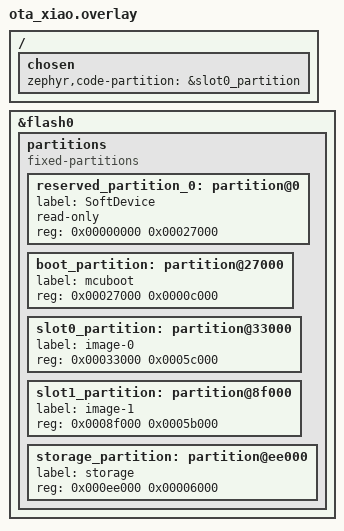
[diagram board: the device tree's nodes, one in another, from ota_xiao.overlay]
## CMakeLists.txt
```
#
# Copyright (c) 2023 Nordic Semiconductor
#
# SPDX-License-Identifier: LicenseRef-Nordic-5-Clause
#
cmake_minimum_required(VERSION 3.20.0)

# Configure VERSION from repository branch and tag
find_package(Git)

if(GIT_EXECUTABLE)
  execute_process(
    COMMAND ${GIT_EXECUTABLE} branch --show-current
    WORKING_DIRECTORY ${CMAKE_SOURCE_DIR}
    OUTPUT_VARIABLE GIT_BRANCH
    )
  execute_process(
    COMMAND ${GIT_EXECUTABLE} describe --dirty --tags --long --match [0-9]*.[0-9]*.[0-9]*
    WORKING_DIRECTORY ${CMAKE_SOURCE_DIR}
    OUTPUT_VARIABLE GIT_VERSION
    )
endif()

# Or from the environment, when git cannot read the checkout (e.g. a Windows git worktree built
# in WSL): FW_GIT_DESCRIBE as the describe command above prints it, and FW_GIT_BRANCH
if(DEFINED ENV{FW_GIT_DESCRIBE})
  set(GIT_VERSION "$ENV{FW_GIT_DESCRIBE}")
  set(GIT_BRANCH "$ENV{FW_GIT_BRANCH}")
endif()

if(GIT_BRANCH STREQUAL "")
  set(GIT_BRANCH unknown)
  message(WARNING "Unknown Git Branch")
endif()

if(GIT_VERSION STREQUAL "")
  set(GIT_VERSION 0.0.0-0)
  message(WARNING "Unknown Tag/Version")
endif()

string(STRIP ${GIT_BRANCH} GIT_BRANCH)
string(STRIP ${GIT_VERSION} GIT_VERSION)
string(REPLACE "-" ";" GIT_VERSION ${GIT_VERSION})
list(GET GIT_VERSION 0 GIT_RELEASE)
list(GET GIT_VERSION 1 GIT_TWEAK)
string(REPLACE "v" "" GIT_RELEASE ${GIT_RELEASE})
string(REPLACE "." ";" GIT_RELEASE ${GIT_RELEASE})
list(GET GIT_RELEASE 0 GIT_MAJOR)
list(GET GIT_RELEASE 1 GIT_MINOR)
list(GET GIT_RELEASE 2 GIT_PATCH)

configure_file(${CMAKE_SOURCE_DIR}/VERSION_SRC ${CMAKE_SOURCE_DIR}/VERSION @ONLY)

# Zephyr
find_package(Zephyr REQUIRED HINTS $ENV{ZEPHYR_BASE})
project(NONE)

# NORDIC SDK APP START
FILE(GLOB_RECURSE app_sources src/*.c)
target_sources(app PRIVATE ${app_sources})

# NORDIC SDK APP END

FILE(GLOB_RECURSE files vqf-c/src/*.c)
target_sources(app PRIVATE ${files})

target_include_directories(app PRIVATE src)
target_include_directories(app PRIVATE vqf-c/src)

# Force recompile for updated build timestamp
add_custom_target(touch_util_h ALL
    COMMAND ${CMAKE_COMMAND} -E touch ${CMAKE_SOURCE_DIR}/src/build_defines.h
)

target_include_directories(app PRIVATE ${CMAKE_CURRENT_SOURCE_DIR}/../shared)
include(${CMAKE_CURRENT_SOURCE_DIR}/../shared/tdma_hw.cmake)
```

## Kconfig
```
#
# Copyright (c) 2023 Nordic Semiconductor
#
# SPDX-License-Identifier: LicenseRef-Nordic-5-Clause
#

config USE_SLIMENRF_CONSOLE
    bool "Use basic console"
    default y
    help
        Use basic console for commands.

config BATTERY_CHARGER_HAS_NTC
    bool "Battery thermistor"
    help
      Flag for battery NTC thermistor availability.

choice
    prompt "Battery voltage mapping"
    default BATTERY_NO_MAPPING

config BATTERY_USE_REG_BUCK_MAPPING
    bool "Use buck regulator mapping (3.7V battery, DCDC)"
    help
      Use a constant power mapping for battery voltage.
      Preffered for systems with a buck regulator.
      Measured at a system voltage of 3.0V.

config BATTERY_USE_REG_LDO_MAPPING
    bool "Use LDO linear regulator mapping (3.7V battery, LDO)"
    help
      Use a constant current mapping for battery voltage.
      Preferred for systems with a linear regulator.

config BATTERY_NO_MAPPING
    bool "Disable battery voltage mapping"
    help
      Always map to 100% battery. Disables battery monitoring.

endchoice

config BATTERY_LOW_RUNTIME_THRESHOLD
    int "Low battery runtime threshold (ms)"
    default 10800000
    help
      Trigger low battery when estimated runtime falls below threshold.
      If estimated runtime is not available, low battery will trigger under 10% estimated state of charge.

choice
    prompt "Status LED color mapping"
    default LED_TRI_COLOR

config LED_RGB_COLOR
    bool "Use RGB color mapping"
    help
        Use RGB or RG color mapping for LED status if available.

config LED_TRI_COLOR
    bool "Use default color mapping"
    help
        Use the default color mapping for LED status.

endchoice

menu "Status LED default status color"
    depends on LED_RGB_COLOR

config LED_DEFAULT_COLOR_R
    int "Red value"
    range 0 10000
    default 4000
    depends on LED_RGB_COLOR
    help
        Red color for default status.
        Valid range is 0 to 10000.

config LED_DEFAULT_COLOR_G
    int "Green value"
    range 0 10000
    default 6000
    depends on LED_RGB_COLOR
    help
        Green color for default status.
        Valid range is 0 to 10000.

config LED_DEFAULT_COLOR_B
    int "Blue value"
    range 0 10000
    default 0
    depends on LED_RGB_COLOR
    help
        Blue color for default status.
        Valid range is 0 to 10000.

endmenu

config USER_EXTRA_ACTIONS
    bool "Multiple press actions"
    help
        Allow user to use multiple presses to calibrate, pair, or enter DFU.
        By default, pairing is available when holding down sw0 for 5 seconds.
        By default, DFU is available when holding down sw0 and plugging in a USB cable.

config IGNORE_RESET
    bool "Ignore reset"
    default y
    help
        If sw0 is available, don't perform any extra actions on reset.

config USER_SHUTDOWN
    bool "User shutdown support"
    default y
    help
        Allow user to use reset or sw0 to shutdown.

config USE_IMU_WAKE_UP
    bool "IMU wake up support"
    default y
    help
        Use IMU wake up state if IMU wake up is present.

config DELAY_SLEEP_ON_STATUS
    bool "Delay IMU wake up mode on status flags"
    default y
    depends on USE_IMU_WAKE_UP
    help
        Delay IMU wake up state if there is an active status flag or in pairing mode.

config WOM_USE_DCDC
    bool "Use DCDC in IMU wake up mode"
    depends on USE_IMU_WAKE_UP
    help
        Use DCDC instead of LDO in IMU wake up state if it is more efficient.

config CONNECTION_TIMEOUT_DELAY
    int "Connection timeout delay (ms)"
    default 300000
    depends on USER_SHUTDOWN
    help
        Connection timeout duration when receiver is not detected.

config TRACKER_OTA
    bool "Firmware updates over the radio (OTA)"
    default y if BOOTLOADER_MCUBOOT
    depends on BOOTLOADER_MCUBOOT
    select FLASH
    select FLASH_MAP
    select STREAM_FLASH
    select IMG_MANAGER
    select IMG_ERASE_PROGRESSIVELY
    help
        Set by the MCUboot build (make tracker-ota). The running image confirms itself once the
        receiver has acknowledged TRACKER_OTA_CONFIRM_ACKS frames; until then MCUboot swaps the
        previous image back on the next reboot. See docs/OTA.md.

config TRACKER_OTA_CONFIRM_ACKS
    int "Acknowledged frames before a new image confirms itself"
    depends on TRACKER_OTA
    default 200
    help
        0 never confirms (for testing the rollback).

config TRACKER_REMOTE_CONFIG
    bool "Settings over the radio"
    default y
    help
        The tracker's settings (list_config) can be read, written and reset from the PC through
        the receiver (tools/remote_config.py, receiver console "cfg"). Works with or without the
        MCUboot build. See docs/OTA.md.

config SENSOR_UPDATE_TIME_MS
    int "Sensor loop period while moving (ms)"
    range 6 33
    default 10
    help
        Default of the sensor_update_time_ms setting (write_config sensor_update_time_ms <6-33>,
        takes effect without a restart). The sensor loop wakes up this often while the tracker
        moves, and sends the orientation when it changed: 10 ms is 100 Hz. Fusion still
        processes every IMU sample from the FIFO; only how often orientations are sent changes.
        Upstream uses 6 ms (about 166 Hz), which with several trackers on one channel fills it
        and makes them collide. Still trackers switch to 33 ms and 100 ms as before.

choice
    prompt "Sensor rotation"
    default SENSOR_ROTATION_90

config SENSOR_ROTATION_0
    bool "0 degrees"

config SENSOR_ROTATION_90
    bool "90 degrees"

config SENSOR_ROTATION_180
    bool "180 degrees"

config SENSOR_ROTATION_270
    bool "270 degrees"

config SENSOR_ROTATION_0_FLIPPED
    bool "0 degrees flipped"

config SENSOR_ROTATION_90_FLIPPED
    bool "90 degrees flipped"

config SENSOR_ROTATION_180_FLIPPED
    bool "180 degrees flipped"

config SENSOR_ROTATION_270_FLIPPED
    bool "270 degrees flipped"

endchoice

menu "Sensor power saving"

config SENSOR_LP_TIMEOUT
    int "Sensor low power delay (ms)"
    default 500
    help
        Low power timeout during no motion.

config SENSOR_USE_LOW_POWER_2
    bool "Use additional low power modes"
    help
        Use a higher latency sensor mode during no motion.

config USE_IMU_TIMEOUT
    bool "Use IMU wake up state"
    default y
    depends on USE_IMU_WAKE_UP
    help
        Use IMU wake up state during no motion.

config IMU_TIMEOUT_RAMP_MIN
    int "Sensor timeout minimum delay (ms)"
    default 5000
    depends on USE_IMU_TIMEOUT || SENSOR_USE_LOW_POWER_2
    help
        Minimum timeout during no motion. Initial period on wake up.

config IMU_TIMEOUT_RAMP_MAX
    int "Sensor timeout maximum delay (ms)"
    default 15000
    depends on USE_IMU_TIMEOUT || SENSOR_USE_LOW_POWER_2
    help
        Maximum timeout during no motion.

config USE_ACTIVE_TIMEOUT
    bool "Use activity timeout"
    default y
    depends on USE_IMU_WAKE_UP || USER_SHUTDOWN
    help
        Delay IMU wake up state or user shutdown during activity.

choice
    prompt "Activity timeout mode"
    default SLEEP_ON_ACTIVE_TIMEOUT
    depends on USE_ACTIVE_TIMEOUT

config SLEEP_ON_ACTIVE_TIMEOUT
    bool "IMU wake up"
    depends on USE_IMU_WAKE_UP
    help
        Use IMU wake up state when activity timeout elapses.

config SHUTDOWN_ON_ACTIVE_TIMEOUT
    bool "User shutdown"
    depends on USER_SHUTDOWN
    help
        Use user shutdown when activity timeout elapses.

endchoice

config ACTIVE_TIMEOUT_THRESHOLD
    int "Activity timeout threshold (ms)"
    default 15000
    depends on USE_ACTIVE_TIMEOUT
    help
        Trigger activity timeout after a certain threshold of activity.

config ACTIVE_TIMEOUT_DELAY
    int "Activity timeout delay (ms)"
    default 900000
    depends on USE_ACTIVE_TIMEOUT
    help
        Activity timeout duration when triggered.

endmenu

config SENSOR_ACCEL_ODR
    int "Accelerometer output data rate (Hz)"
    default 100
    help
        Requested accelerometer output data rate. Actual rate will be raised to the nearest supported rate.
        A higher rate will increase the time to read and process sensor data.

config SENSOR_GYRO_ODR
    int "Gyrometer output data rate (Hz)"
    default 200
    help
        Requested gyrometer output data rate. Actual rate will be raised to the nearest supported rate.
        A higher rate will increase the time to read and process sensor data.
        A lower rate is recommended for IMUs with poor gyrometer rate noise density. (e.g. BMI270, LSM6DS3TR-C)

config SENSOR_ACCEL_FS
    int "Accelerometer full scale (g)"
    default 4
    help
        Requested accelerometer full scale. Actual scale will be raised to the nearest supported scale.
        A lower scale may improve noise performance, but is more likely to saturate.

config SENSOR_GYRO_FS
    int "Gyrometer full scale (dps)"
    default 1000
    help
        Requested gyrometer full scale. Actual scale will be raised to the nearest supported scale.
        A lower scale may improve noise performance, but is more likely to saturate.

config SENSOR_USE_MAG
    bool "Magnetometer support"
    default y
    help
        Use magnetometer if it is present.

config USE_SENSOR_CLOCK
    bool "Use external IMU clock"
    default y
    help
        Use external IMU clock if it is present.

choice
    prompt "Sensor fusion"
    default SENSOR_USE_VQF
    help
        Select the sensor fusion method.

config SENSOR_USE_VQF
    bool "Use VQF"
    help
        Use VQF for sensor fusion.
        Based on Kalman filter.

endchoice

config SENSOR_USE_6_SIDE_CALIBRATION
    bool "Use 6-side calibration"
    default y
    depends on USE_SLIMENRF_CONSOLE
    help
        Use 6-side calibration for accelerometer.
        Calibration can be completed through the basic console.

config RADIO_TX_POWER
    int "Radio output power (dBm)"
    default 8
    help
        Radio output power level.
        A lower value may reduce power consumption.

config CONNECTION_OVER_HID
    bool "Use HID for data output"
    help
        Use HID if available.
        Otherwise, use ESB only.

config TRACKER_BLE
    bool "BLE connection mode"
    default y if SOC_NRF52840
    select BT
    select BT_PERIPHERAL
    select BT_DEVICE_NAME_DYNAMIC
    select ESB_DYNAMIC_INTERRUPTS
    select MPSL_DYNAMIC_INTERRUPTS
    help
        Builds the BLE stack in beside ESB. The connection_over_ble setting (console: ble on|off)
        picks one at boot: the radio runs either ESB to the receiver or BLE to a PC
        (tools/ble_bridge.py), never both. Changing it reboots the tracker.

        MPSL keeps its own (default) clock control in both modes: it runs the 32 MHz crystal
        that USB and the radio share. In ESB mode MPSL stays initialized but idle, and ESB takes
        the radio interrupt over (dynamic interrupts). MPSL_USE_EXTERNAL_CLOCK_CONTROL
        (experimental on nRF52) left USB stalled and BLE connections failing: not used.

config CONNECTION_OVER_BLE
    bool "Start in BLE mode"
    depends on TRACKER_BLE
    help
        Default of the connection_over_ble setting.

if TRACKER_BLE

config BT_DEVICE_NAME
    default "SlimeNRF"

# ble.c names the tracker SlimeNRF-<last 4 hex digits of its address>; not renamable over the air
config BT_DEVICE_NAME_GATT_WRITABLE
    default n

# 7.5-15 ms: one notification per connection event keeps up with the ~120 Hz moving rate
config BT_PERIPHERAL_PREF_MIN_INT
    default 6

config BT_PERIPHERAL_PREF_MAX_INT
    default 12

config BT_PERIPHERAL_PREF_TIMEOUT
    default 400

choice BT_CTLR_TX_PWR
    default BT_CTLR_TX_PWR_PLUS_8
endchoice

endif

# BLE needs a calibrated RC clock (500 ppm). Without BLE it stays off for a faster boot, as before.
config CLOCK_CONTROL_NRF_K32SRC_RC_CALIBRATION
    default n if !TRACKER_BLE

source "Kconfig.zephyr"
```

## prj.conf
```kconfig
#CONFIG_NCS_SAMPLES_DEFAULTS
CONFIG_ASSERT=y
CONFIG_ASSERT_NO_COND_INFO=y
CONFIG_ASSERT_NO_MSG_INFO=y
CONFIG_RESET_ON_FATAL_ERROR=y

CONFIG_NCS_APPLICATION_BOOT_BANNER_STRING="SlimeVR-Tracker-nRF"
#CONFIG_NCS_BOOT_BANNER=n
CONFIG_BOOT_BANNER=n

# Always active, as SlimeVR's "Sleep (WOM) off" builds: no wake-on-motion power-off when still.
# The activity timeout goes too: without WOM it would fall back to a full shutdown after 15 min
# still. The shutdown after losing the receiver (connection_timeout_delay) stays.
CONFIG_USE_IMU_WAKE_UP=n
CONFIG_USE_ACTIVE_TIMEOUT=n

CONFIG_ESB=y
#need to enable for nRF54L
#CONFIG_NRFX_DPPI10=y

CONFIG_ADC=y
CONFIG_ADC_NRFX_SAADC=y
CONFIG_FPU=y
CONFIG_I2C=y
CONFIG_SPI=y
CONFIG_PINCTRL=y
CONFIG_SENSOR=y

CONFIG_CMSIS_DSP=y
CONFIG_CMSIS_DSP_BASICMATH=y
CONFIG_CMSIS_DSP_CONTROLLER=y
CONFIG_CMSIS_DSP_FASTMATH=y
CONFIG_CMSIS_DSP_SUPPORT=y

CONFIG_NVS=y
CONFIG_NVS_LOOKUP_CACHE=y
CONFIG_NVS_INIT_BAD_MEMORY_REGION=y

CONFIG_POWEROFF=y
CONFIG_REBOOT=y

CONFIG_FLASH=y
CONFIG_FLASH_PAGE_LAYOUT=y
CONFIG_FLASH_MAP=y

CONFIG_SETTINGS=y
CONFIG_SETTINGS_RUNTIME=y
CONFIG_SETTINGS_NONE=y

CONFIG_MPU_ALLOW_FLASH_WRITE=y

CONFIG_RETAINED_MEM=y

CONFIG_USE_SEGGER_RTT=y
CONFIG_LOG=y
#CONFIG_PRINTK=y
CONFIG_LOG_MODE_DEFERRED=y
CONFIG_LOG_SPEED=y
CONFIG_LOG_BACKEND_RTT=y
CONFIG_CBPRINTF_FP_SUPPORT=y
CONFIG_ADC_LOG_LEVEL_OFF=y
CONFIG_LOG_FUNC_NAME_PREFIX_ERR=y
CONFIG_LOG_BUFFER_SIZE=1536
CONFIG_LOG_BACKEND_UART_AUTOSTART=n
CONFIG_LOG_PROCESS_THREAD_SLEEP_MS=50
CONFIG_LOG_PROCESS_THREAD_STACK_SIZE=1024

CONFIG_PWM=y
CONFIG_GPIO=y

CONFIG_CRC=y

CONFIG_NEWLIB_LIBC=y
#deprecated?
#CONFIG_NRFX_TIMER1=y

#speed up boot? (use internal rc oscillator)
CONFIG_CLOCK_CONTROL_NRF_K32SRC_RC=y
# calibration: off unless the BLE mode is built in (Kconfig, TRACKER_BLE)
#speed up boot? (synthesize lf clock)
#CONFIG_CLOCK_CONTROL_NRF_K32SRC_SYNTH=y

# dont need it
CONFIG_CRYPTO=n

# set timeout for 25ms, sufficient for ~1000 bytes
CONFIG_I2C_NRFX_TRANSFER_TIMEOUT=25

CONFIG_USB_DEVICE_HID=y
CONFIG_USB_DEVICE_VID=0x1209
CONFIG_USB_DEVICE_PID=0x7692
CONFIG_USB_HID_BOOT_PROTOCOL=y
CONFIG_USB_DEVICE_INITIALIZE_AT_BOOT=n
CONFIG_USB_CDC_ACM=y
CONFIG_UART_INTERRUPT_DRIVEN=y
CONFIG_USB_WORKQUEUE_STACK_SIZE=512

CONFIG_SERIAL=y
CONFIG_CONSOLE=y
CONFIG_RTT_CONSOLE=y
CONFIG_UART_CONSOLE=y
CONFIG_UART_LINE_CTRL=y
# fit "write all <base64:173>"
CONFIG_CONSOLE_INPUT_MAX_LINE_LEN=256

CONFIG_LOG=y
CONFIG_USB_DRIVER_LOG_LEVEL_ERR=y
CONFIG_USB_DEVICE_LOG_LEVEL_ERR=y
CONFIG_USB_CDC_ACM_LOG_LEVEL_OFF=y

CONFIG_LOG_BACKEND_UART=y

CONFIG_CONSOLE_SUBSYS=y
CONFIG_CONSOLE_GETLINE=y

CONFIG_NVS_LOG_LEVEL_WRN=y
CONFIG_USB_HID_LOG_LEVEL_WRN=y

CONFIG_USB_DEVICE_SOF=y
CONFIG_USB_HID_REPORTS=256

#CONFIG_USB_HID_POLL_INTERVAL_MS=1
CONFIG_USB_HID_POLL_INTERVAL_MS=0
CONFIG_HID_INTERRUPT_EP_MPS=64
#CONFIG_ENABLE_HID_INT_OUT_EP=y

# the BLE host (TRACKER_BLE) runs on the system workqueue; upstream had 256
CONFIG_SYSTEM_WORKQUEUE_STACK_SIZE=1024
CONFIG_MAIN_STACK_SIZE=512
#crashing on nrf54l at 512

CONFIG_THREAD_NAME=y

# Hardware watchdog (src/system/watchdog.c): a tracker whose threads stop running resets itself
CONFIG_WATCHDOG=y

CONFIG_HEAP_MEM_POOL_SIZE=2048
CONFIG_ISR_STACK_SIZE=1024

CONFIG_PM_DEVICE=y

CONFIG_BASE64=y

#CONFIG_THREAD_ANALYZER=y
#CONFIG_THREAD_ANALYZER_AUTO=y
#CONFIG_THREAD_ANALYZER_AUTO_INTERVAL=5

#about 20KB saved
#CONFIG_LTO=y
#CONFIG_ISR_TABLES_LOCAL_DECLARATION=y
```

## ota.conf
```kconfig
# Tracker app in the OTA build (make tracker-ota passes it as Tracker_EXTRA_CONF_FILE): the
# partition manager places it behind MCUboot (pm_static/mcuboot_*.yml), not at the UF2 offset the
# board defconfig sets.
CONFIG_FLASH_LOAD_OFFSET=0x0
```

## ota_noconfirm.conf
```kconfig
# Rollback test (make tracker-ota-slot1 OTA_NOCONFIRM=1): this image never confirms itself, so
# MCUboot swaps the previous one back on the next reboot.
CONFIG_TRACKER_OTA_CONFIRM_ACKS=0
```

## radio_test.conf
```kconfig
CONFIG_RADIO_TDMA=y
CONFIG_RADIO_TEST=y
CONFIG_RADIO_TEST_HZ=100
CONFIG_STACK_USAGE=y
```

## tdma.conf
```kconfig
# Experimental; requires the matching receiver and TDMA firmware on every tracker.
CONFIG_RADIO_TDMA=y
CONFIG_STACK_USAGE=y
```

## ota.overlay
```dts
/* Tracker app in the OTA build (make tracker-ota passes it as Tracker_EXTRA_DTC_OVERLAY_FILE): the
 * partition labels MCUboot's image tools need, the same layout as pm_static/mcuboot_nrf52840_uf2.yml
 * (which the build uses for the actual placement) and sysbuild/mcuboot.overlay. */
&flash0 {
	partitions {
		compatible = "fixed-partitions";
		#address-cells = <1>;
		#size-cells = <1>;

		boot_partition: partition@1000 {
			label = "mcuboot";
			reg = <0x00001000 0x0000c000>;
		};
		slot0_partition: partition@d000 {
			label = "image-0";
			reg = <0x0000d000 0x0006f000>;
		};
		slot1_partition: partition@7c000 {
			label = "image-1";
			reg = <0x0007c000 0x0006e000>;
		};
		storage_partition: partition@ee000 {
			label = "storage";
			reg = <0x000ee000 0x00006000>;
		};
	};
};
```

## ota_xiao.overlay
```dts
/* Tracker app in the XIAO OTA build (make tracker-ota-xiao passes it as Tracker_EXTRA_DTC_OVERLAY_FILE):
 * the partition labels MCUboot's image tools need, the same layout as pm_static/mcuboot_xiao_ble.yml
 * (which the build uses for the actual placement) and sysbuild/mcuboot_xiao.overlay. The board's
 * own table names its UF2 bootloader boot_partition, so the table is replaced, not extended. */
/ {
	chosen {
		zephyr,code-partition = &slot0_partition;
	};
};

&flash0 {
	/delete-node/ partitions;

	partitions {
		compatible = "fixed-partitions";
		#address-cells = <1>;
		#size-cells = <1>;

		reserved_partition_0: partition@0 {
			label = "SoftDevice";
			read-only;
			reg = <0x00000000 0x00027000>;
		};
		boot_partition: partition@27000 {
			label = "mcuboot";
			reg = <0x00027000 0x0000c000>;
		};
		slot0_partition: partition@33000 {
			label = "image-0";
			reg = <0x00033000 0x0005c000>;
		};
		slot1_partition: partition@8f000 {
			label = "image-1";
			reg = <0x0008f000 0x0005b000>;
		};
		storage_partition: partition@ee000 {
			label = "storage";
			reg = <0x000ee000 0x00006000>;
		};
	};
};
```

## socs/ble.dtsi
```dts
/* BLE mode (CONFIG_TRACKER_BLE, included by the nrf52840*.overlay files): random numbers from the
 * RNG peripheral. The SoC default is CryptoCell, whose driver needs nrf_security. */
/ {
	chosen {
		zephyr,entropy = &rng;
	};
};
```

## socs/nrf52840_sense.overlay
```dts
/ {
	sram0@2003f000 {
		compatible = "zephyr,memory-region", "mmio-sram";
		reg = <0x2003f000 DT_SIZE_K(4)>;
		zephyr,memory-region = "RETAINED_MEM";
		status = "okay";

		retainedmem0: retainedmem {
			compatible = "zephyr,retained-ram";
			status = "okay";
		};
	};

	sram0@20007f7c {
		compatible = "zephyr,memory-region", "mmio-sram";
		reg = <0x20007f7c 4>;
		zephyr,memory-region = "DFU_DBL_RESET_MEM";
		status = "okay";

		retainedmem {
			compatible = "zephyr,retained-ram";
			status = "okay";
		};
	};

	aliases {
		retainedmemdevice = &retainedmem0;
	};
};

&sram0 {
	/* Shrink SRAM size to avoid overlap with retained memory region */
	reg = <0x20000000 DT_SIZE_K(252)>;
};

#include "ble.dtsi" /* BLE mode (CONFIG_TRACKER_BLE) */
```

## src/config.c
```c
#include "globals.h"
#include "system/system.h"

#include "config.h"

#if DT_NODE_HAS_STATUS_OKAY(DT_ALIAS(retainedmemdevice))
#define MEMORY_REGION DT_PARENT(DT_ALIAS(retainedmemdevice))
#else
#error "retained_mem region not defined"
#endif

#define RETAINED_SETTINGS_OFFSET offsetof(struct retained_data, settings)

struct config_settings_data *config_settings = (struct config_settings_data *)(DT_REG_ADDR(MEMORY_REGION) + RETAINED_SETTINGS_OFFSET);

const uint16_t config_settings_count[] = {
	CONFIG_0_SETTINGS_END,
	CONFIG_1_SETTINGS_END,
	CONFIG_2_SETTINGS_END,
	CONFIG_3_SETTINGS_END
};

const char *config_settings_names[] = {
	"user_extra_actions", // 0
	"ignore_reset",
	"user_shutdown",
	"use_imu_wake_up",
	"delay_sleep_on_status",
	"connection_over_hid",
	"sensor_use_low_power_2", // 1
	"use_imu_timeout",
	"use_active_timeout",
	"sensor_use_mag",
	"use_sensor_clock",
	"sensor_use_6_side_calibration",
	"led_default_color_r", // 2
	"led_default_color_g",
	"led_default_color_b",
	"active_timeout_mode",
	"sensor_accel_odr",
	"sensor_gyro_odr",
	"sensor_accel_fs",
	"sensor_gyro_fs",
	"sensor_fusion",
	"radio_tx_power",
	"connection_timeout_delay", // 3
	"sensor_lp_timeout",
	"imu_timeout_ramp_min",
	"imu_timeout_ramp_max",
	"active_timeout_threshold",
	"active_timeout_delay",
	"battery_low_runtime_threshold",
	"sensor_update_time_ms",
	"connection_over_ble",
	"sensor_send_unchanged"
};

const bool config_0_settings_defaults[16] = {
	IS_ENABLED(CONFIG_USER_EXTRA_ACTIONS),
	IS_ENABLED(CONFIG_IGNORE_RESET),
	IS_ENABLED(CONFIG_USER_SHUTDOWN),
	IS_ENABLED(CONFIG_USE_IMU_WAKE_UP),
	IS_ENABLED(CONFIG_DELAY_SLEEP_ON_STATUS),
	IS_ENABLED(CONFIG_CONNECTION_OVER_HID),
};

const bool config_1_settings_defaults[16] = {
	IS_ENABLED(CONFIG_SENSOR_USE_LOW_POWER_2),
	IS_ENABLED(CONFIG_USE_IMU_TIMEOUT),
	IS_ENABLED(CONFIG_USE_ACTIVE_TIMEOUT),
	IS_ENABLED(CONFIG_SENSOR_USE_MAG),
	IS_ENABLED(CONFIG_USE_SENSOR_CLOCK),
	IS_ENABLED(CONFIG_SENSOR_USE_6_SIDE_CALIBRATION),
};

const int16_t config_2_settings_defaults[16] = {
#ifdef CONFIG_LED_DEFAULT_COLOR_R
	CONFIG_LED_DEFAULT_COLOR_R, // 0-10000
#else
	4000,
#endif
#ifdef CONFIG_LED_DEFAULT_COLOR_G
	CONFIG_LED_DEFAULT_COLOR_G, // 0-10000
#else
	6000,
#endif
#ifdef CONFIG_LED_DEFAULT_COLOR_B
	CONFIG_LED_DEFAULT_COLOR_B, // 0-10000
#else
	0,
#endif
#if CONFIG_SHUTDOWN_ON_ACTIVE_TIMEOUT
	1,
#else // CONFIG_SLEEP_ON_ACTIVE_TIMEOUT
	0,
#endif
	CONFIG_SENSOR_ACCEL_ODR, // 0-3200 (e.g.)
	CONFIG_SENSOR_GYRO_ODR, // 0-3200 (e.g.)
	CONFIG_SENSOR_ACCEL_FS, // 0-32000 (e.g.)
	CONFIG_SENSOR_GYRO_FS, // 0-32000 (e.g.)
#if CONFIG_SENSOR_USE_VQF
	3,
#elif CONFIG_SENSOR_USE_NXPSENSORFUSION
	2,
#elif CONFIG_SENSOR_USE_XIOFUSION
	1,
#else
	0,
#endif
	CONFIG_RADIO_TX_POWER, // -128-127
};

const int32_t config_3_settings_defaults[16] = {
#ifdef CONFIG_CONNECTION_TIMEOUT_DELAY
	CONFIG_CONNECTION_TIMEOUT_DELAY,
#else
	300000,
#endif
	CONFIG_SENSOR_LP_TIMEOUT,
#ifdef CONFIG_IMU_TIMEOUT_RAMP_MIN
	CONFIG_IMU_TIMEOUT_RAMP_MIN,
#else
	5000,
#endif
#ifdef CONFIG_IMU_TIMEOUT_RAMP_MAX
	CONFIG_IMU_TIMEOUT_RAMP_MAX,
#else
	15000,
#endif
#ifdef CONFIG_ACTIVE_TIMEOUT_THRESHOLD
	CONFIG_ACTIVE_TIMEOUT_THRESHOLD,
#else
	15000,
#endif
#ifdef CONFIG_ACTIVE_TIMEOUT_DELAY
	CONFIG_ACTIVE_TIMEOUT_DELAY,
#else
	900000,
#endif
	CONFIG_BATTERY_LOW_RUNTIME_THRESHOLD,
	CONFIG_SENSOR_UPDATE_TIME_MS, // 6-33, see sensor_low_noise_update_time_ms
	IS_ENABLED(CONFIG_CONNECTION_OVER_BLE), // 0-1, see ble.c
	0, // 0-1, see sensor.c
};

LOG_MODULE_REGISTER(config, LOG_LEVEL_INF);

void config_settings_init(void)
{
	for (int i = 0; i < 16; i++)
	{
		uint16_t write_mask = 1 << i;
		if (!(config_settings->config_0_ovrd & write_mask))
		{
			if (config_0_settings_defaults[i])
				config_settings->config_0_settings |= write_mask;
			else
				config_settings->config_0_settings &= ~write_mask;
		}
		if (!(config_settings->config_1_ovrd & write_mask))
		{
			if (config_1_settings_defaults[i])
				config_settings->config_1_settings |= write_mask;
			else
				config_settings->config_1_settings &= ~write_mask;
		}
		if (!(config_settings->config_2_ovrd & write_mask))
			config_settings->config_2_settings[i] = config_2_settings_defaults[i];
		if (!(config_settings->config_3_ovrd & write_mask))
			config_settings->config_3_settings[i] = config_3_settings_defaults[i];
	}
}

void config_0_settings_write(uint16_t id, bool value)
{
	uint16_t write_mask = 1 << id;

	config_settings->config_0_ovrd |= write_mask;

	if (value)
		config_settings->config_0_settings |= write_mask;
	else
		config_settings->config_0_settings &= ~write_mask;

	sys_write(SETTINGS_ID, NULL, retained->settings, sizeof(retained->settings));
}

void config_1_settings_write(uint16_t id, bool value)
{
	uint16_t write_mask = 1 << id;

	config_settings->config_1_ovrd |= write_mask;

	if (value)
		config_settings->config_1_settings |= write_mask;
	else
		config_settings->config_1_settings &= ~write_mask;

	sys_write(SETTINGS_ID, NULL, retained->settings, sizeof(retained->settings));
}

void config_2_settings_write(uint16_t id, int16_t value)
{
	uint16_t write_mask = 1 << id;

	config_settings->config_2_ovrd |= write_mask;

	config_settings->config_2_settings[id] = value;

	sys_write(SETTINGS_ID, NULL, retained->settings, sizeof(retained->settings));
}

void config_3_settings_write(uint16_t id, int32_t value)
{
	uint16_t write_mask = 1 << id;

	config_settings->config_3_ovrd |= write_mask;

	config_settings->config_3_settings[id] = value;

	sys_write(SETTINGS_ID, NULL, retained->settings, sizeof(retained->settings));
}

void config_settings_reset(uint16_t config, uint16_t id)
{
	uint16_t write_mask = 1 << id;

	switch (config)
	{
	case 0:
		config_settings->config_0_ovrd &= ~write_mask;
		break;
	case 1:
		config_settings->config_1_ovrd &= ~write_mask;
		break;
	case 2:
		config_settings->config_2_ovrd &= ~write_mask;
		break;
	case 3:
		config_settings->config_3_ovrd &= ~write_mask;
		break;
	default:
	}

	config_settings_init(); // reset non-overridden value

	sys_write(SETTINGS_ID, NULL, retained->settings, sizeof(retained->settings));
}

void config_settings_reset_all(void)
{
	static bool reset_confirm = false;
	if (!reset_confirm)
	{
		printk("Resetting device settings will clear all user-defined settings to the firmware defaults. Please resend the command to confirm.\n");
		reset_confirm = true;
		return;
	}
	printk("Resetting device settings\n");

	config_settings->config_0_ovrd = 0;
	config_settings->config_1_ovrd = 0;
	config_settings->config_2_ovrd = 0;
	config_settings->config_3_ovrd = 0;

	config_settings_init(); // reset non-overridden value

	sys_write(SETTINGS_ID, NULL, retained->settings, sizeof(retained->settings));
	reset_confirm = false;
	LOG_INF("Device settings reset");
}
```

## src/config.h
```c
#ifndef SLIMENRF_CONFIG
#define SLIMENRF_CONFIG

#include "retained.h"

#define CONFIG_SETTINGS_COUNT 4

// map of settings area
struct config_settings_data {
	uint16_t config_0_ovrd; // Override enable flags
	uint16_t config_0_settings;
	uint16_t config_1_ovrd;
	uint16_t config_1_settings;
	uint16_t config_2_ovrd;
	int16_t config_2_settings[16];
	uint16_t config_3_ovrd;
	int32_t config_3_settings[16];
};

// because settings read is a macro, need to expose settings struct
extern struct config_settings_data *config_settings;

// device settings
enum config_0_settings_id {
	CONFIG_0_USER_EXTRA_ACTIONS,
	CONFIG_0_IGNORE_RESET,
	CONFIG_0_USER_SHUTDOWN,
	CONFIG_0_USE_IMU_WAKE_UP,
	CONFIG_0_DELAY_SLEEP_ON_STATUS,
	CONFIG_0_CONNECTION_OVER_HID,
	CONFIG_0_SETTINGS_END
};

// sensor settings
enum config_1_settings_id {
	CONFIG_1_SENSOR_USE_LOW_POWER_2,
	CONFIG_1_USE_IMU_TIMEOUT,
	CONFIG_1_USE_ACTIVE_TIMEOUT,
	CONFIG_1_SENSOR_USE_MAG,
	CONFIG_1_USE_SENSOR_CLOCK,
	CONFIG_1_SENSOR_USE_6_SIDE_CALIBRATION,
	CONFIG_1_SETTINGS_END
};

enum config_2_settings_id {
	CONFIG_2_LED_DEFAULT_COLOR_R,
	CONFIG_2_LED_DEFAULT_COLOR_G,
	CONFIG_2_LED_DEFAULT_COLOR_B,
	CONFIG_2_ACTIVE_TIMEOUT_MODE, // 0: Sleep, 1: Shutdown
	CONFIG_2_SENSOR_ACCEL_ODR,
	CONFIG_2_SENSOR_GYRO_ODR,
	CONFIG_2_SENSOR_ACCEL_FS,
	CONFIG_2_SENSOR_GYRO_FS,
	CONFIG_2_SENSOR_FUSION, // 1: XIO, 3: VQF
	CONFIG_2_RADIO_TX_POWER,
	CONFIG_2_SETTINGS_END
};

enum config_3_settings_id {
	CONFIG_3_CONNECTION_TIMEOUT_DELAY,
	CONFIG_3_SENSOR_LP_TIMEOUT,
	CONFIG_3_IMU_TIMEOUT_RAMP_MIN,
	CONFIG_3_IMU_TIMEOUT_RAMP_MAX,
	CONFIG_3_ACTIVE_TIMEOUT_THRESHOLD,
	CONFIG_3_ACTIVE_TIMEOUT_DELAY,
	CONFIG_3_BATTERY_LOW_RUNTIME_THRESHOLD,
	CONFIG_3_SENSOR_UPDATE_TIME_MS, // appended so the ids of the other settings stay the same
	CONFIG_3_CONNECTION_OVER_BLE, // 0: ESB, 1: BLE; read at boot (ble on|off)
	CONFIG_3_SENSOR_SEND_UNCHANGED, // 0-1: send every update, also while the orientation stays the same (load tests)
	CONFIG_3_SETTINGS_END
};

extern const uint16_t config_settings_count[];

extern const char *config_settings_names[];

#define CONFIG_0_SETTINGS_READ(id) (config_settings->config_0_settings & (1 << id))
#define CONFIG_1_SETTINGS_READ(id) (config_settings->config_1_settings & (1 << id))
#define CONFIG_2_SETTINGS_READ(id) (config_settings->config_2_settings[id])
#define CONFIG_3_SETTINGS_READ(id) (config_settings->config_3_settings[id])

void config_settings_init(void);

void config_0_settings_write(uint16_t id, bool value);
void config_1_settings_write(uint16_t id, bool value);
void config_2_settings_write(uint16_t id, int16_t value);
void config_3_settings_write(uint16_t id, int32_t value);

void config_settings_reset(uint16_t config, uint16_t id);
void config_settings_reset_all(void);

#endif
```

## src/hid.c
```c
/*
	SlimeVR Code is placed under the MIT license
	Copyright (c) 2025 SlimeVR Contributors

	Permission is hereby granted, free of charge, to any person obtaining a copy
	of this software and associated documentation files (the "Software"), to deal
	in the Software without restriction, including without limitation the rights
	to use, copy, modify, merge, publish, distribute, sublicense, and/or sell
	copies of the Software, and to permit persons to whom the Software is
	furnished to do so, subject to the following conditions:

	The above copyright notice and this permission notice shall be included in
	all copies or substantial portions of the Software.

	THE SOFTWARE IS PROVIDED "AS IS", WITHOUT WARRANTY OF ANY KIND, EXPRESS OR
	IMPLIED, INCLUDING BUT NOT LIMITED TO THE WARRANTIES OF MERCHANTABILITY,
	FITNESS FOR A PARTICULAR PURPOSE AND NONINFRINGEMENT. IN NO EVENT SHALL THE
	AUTHORS OR COPYRIGHT HOLDERS BE LIABLE FOR ANY CLAIM, DAMAGES OR OTHER
	LIABILITY, WHETHER IN AN ACTION OF CONTRACT, TORT OR OTHERWISE, ARISING FROM,
	OUT OF OR IN CONNECTION WITH THE SOFTWARE OR THE USE OR OTHER DEALINGS IN
	THE SOFTWARE.
*/
#include "globals.h"

#if CONFIG_USB_DEVICE_STACK
#define USB DT_NODELABEL(usbd)
#define USB_EXISTS (DT_NODE_HAS_STATUS(USB, okay) && CONFIG_UART_CONSOLE)
#endif

#if USB_EXISTS
#include <zephyr/kernel.h>
#include <zephyr/usb/usb_device.h>
#include <zephyr/usb/class/usb_hid.h>

static struct tracker_report {
	uint8_t data[16];
} __packed report = {
	.data = {0}
};;

#define REPORT_SIZE sizeof(report)
#define REPORT_COUNT (3 * 4)
#define REPORT_THRESHOLD (REPORT_COUNT - 4) // buffer loop point

uint8_t reports[REPORT_COUNT * REPORT_SIZE]; // 3 report buffer (and 4 "packets" each)
uint8_t report_count = 0;
uint8_t report_sent = 0;

static const struct device *hdev;
static ATOMIC_DEFINE(hid_ep_in_busy, 1);

#define HID_EP_BUSY_FLAG 0

LOG_MODULE_REGISTER(hid_event, LOG_LEVEL_INF);

static void hid_thread(void);
static struct k_thread hid_thread_id;
static K_THREAD_STACK_DEFINE(hid_thread_id_stack, 256);

static const uint8_t hid_report_desc[] = {
	HID_USAGE_PAGE(HID_USAGE_GEN_DESKTOP),
	HID_USAGE(HID_USAGE_GEN_DESKTOP_UNDEFINED),
	HID_COLLECTION(HID_COLLECTION_APPLICATION),
		HID_USAGE(HID_USAGE_GEN_DESKTOP_UNDEFINED),
		HID_REPORT_SIZE(8),
		HID_REPORT_COUNT(64),
		HID_INPUT(0x02),
	HID_END_COLLECTION,
};

// Created and aborted once each, as the console thread (console.c console_thread_create)
static atomic_t hid_thread_running;

void hid_thread_create(void)
{
	if (!atomic_cas(&hid_thread_running, 0, 1))
		return;
	k_thread_create(&hid_thread_id, hid_thread_id_stack, K_THREAD_STACK_SIZEOF(hid_thread_id_stack), (k_thread_entry_t)hid_thread, NULL, NULL, NULL, HID_THREAD_PRIORITY, 0, K_NO_WAIT);
}

void hid_thread_abort(void)
{
	if (!atomic_cas(&hid_thread_running, 1, 0))
		return;
	k_thread_abort(&hid_thread_id);
}

static void packet_device_addr(uint8_t *report) // associate id and tracker address
{
	report[0] = 255; // receiver packet 0
	report[1] = 0; // for hid on tracker, id is always 0
	uint64_t *addr = (uint64_t *)NRF_FICR->DEVICEADDR; // Use device address as unique identifier (although it is not actually guaranteed, see datasheet)
	memcpy(&report[2], addr, 6);
	memset(&report[8], 0, 8); // last 8 bytes unused for now
}

static uint32_t dropped_reports = 0;
static uint16_t max_dropped_reports = 0;

int64_t last_registration_sent = 0;

#define REGISTRATION_INTERVAL 100

static void send_report()
{
	if (report_count == 0 && k_uptime_get() - REGISTRATION_INTERVAL < last_registration_sent) // send registrations only every 100ms (also acting as a keep alive)
		return;

	int ret, wrote;

	last_registration_sent = k_uptime_get();

	if (!atomic_test_and_set_bit(hid_ep_in_busy, HID_EP_BUSY_FLAG))
	{
		// fill report; send associated address for server to register
		for (int i = report_count; i < 4; i++)
			packet_device_addr(&reports[REPORT_SIZE * (report_sent + i)]);

		ret = hid_int_ep_write(hdev, &reports[REPORT_SIZE * report_sent], REPORT_SIZE * 4, &wrote);
		report_sent += 4;

		// track if more reports were waiting than sent
		if (report_count > 4)
		{
			dropped_reports += report_count - 4;
			if (dropped_reports > max_dropped_reports)
				max_dropped_reports = dropped_reports;
		}

		// loop counters
		if (report_sent >= REPORT_THRESHOLD)
			report_sent = 0;
		report_count = 0;

		if (ret != 0)
		{
			/*
			 * Do nothing and wait until host has reset the device
			 * and hid_ep_in_busy is cleared.
			 */
			LOG_ERR("Failed to submit report");
		}
	}
}

int64_t last_dropped_report_log = 0;

#define DROPPED_REPORT_LOG_INTERVAL 5000

void hid_thread(void)
{
	while (1)
	{
		send_report();

		if (k_uptime_get() - DROPPED_REPORT_LOG_INTERVAL > last_dropped_report_log)
		{
			if (dropped_reports)
    	        LOG_INF("Dropped reports: %u (max: %u)", dropped_reports, max_dropped_reports);
			dropped_reports = 0;
			max_dropped_reports = 0;
			last_dropped_report_log = k_uptime_get();
		}

		k_msleep(1);
	}
}

static void int_in_ready_cb(const struct device *dev)
{
	ARG_UNUSED(dev);
	if (!atomic_test_and_clear_bit(hid_ep_in_busy, HID_EP_BUSY_FLAG))
		LOG_WRN("IN endpoint callback without preceding buffer write");
}

void hid_int_in_ready(void)
{
	int_in_ready_cb(hdev);
}

/*
 * On Idle callback is available here as an example even if actual use is
 * very limited. In contrast to report_event_handler(),
 * report value is not incremented here.
 */
static void on_idle_cb(const struct device *dev, uint16_t report_id)
{
	LOG_DBG("On idle callback");
}

static void protocol_cb(const struct device *dev, uint8_t protocol)
{
	LOG_INF("New protocol: %s", protocol == HID_PROTOCOL_BOOT ? "boot" : "report");
}

static const struct hid_ops ops = {
	.int_in_ready = int_in_ready_cb,
	.on_idle = on_idle_cb,
	.protocol_change = protocol_cb,
};

static int composite_pre_init(void)
{
	hdev = device_get_binding("HID_0");
	if (hdev == NULL)
	{
		LOG_ERR("Cannot get USB HID Device");
		return -ENODEV;
	}

	LOG_INF("HID Device: dev %p", hdev);

	usb_hid_register_device(hdev, hid_report_desc, sizeof(hid_report_desc), &ops);

	atomic_set_bit(hid_ep_in_busy, HID_EP_BUSY_FLAG);

	if (usb_hid_set_proto_code(hdev, HID_BOOT_IFACE_CODE_NONE))
		LOG_WRN("Failed to set Protocol Code");

	return usb_hid_init(hdev);
}

SYS_INIT(composite_pre_init, APPLICATION, CONFIG_KERNEL_INIT_PRIORITY_DEVICE);
#endif

//|b0      |b1      |b2      |b3      |b4      |b5      |b6      |b7      |b8      |b9      |b10     |b11     |b12     |b13     |b14     |b15     |
//|type    |id      |packet data                                                                                                                  |
//|0       |id      |proto   |batt    |batt_v  |temp    |brd_id  |mcu_id  |imu_id  |mag_id  |fw_date          |major   |minor   |patch   |rssi    |
//|1       |id      |q0               |q1               |q2               |q3               |a0               |a1               |a2               |
//|2       |id      |batt    |batt_v  |temp    |q_buf                              |a0               |a1               |a2               |rssi    |
//|3	   |id      |svr_stat|status  |resv                                                                                              |rssi    |
//|4       |id      |q0               |q1               |q2               |q3               |m0               |m1               |m2               |
//|255     |id      |addr                                                 |resv                                                                   |

void hid_write_packet_n(uint8_t *data)
{
#if USB_EXISTS
	if (CONFIG_0_SETTINGS_READ(CONFIG_0_CONNECTION_OVER_HID))
	{
		memcpy(&report.data, data, 16); // all data can be passed through
		if (data[0] != 1 && data[0] != 4) // packet 1 and 4 are full precision quat and accel/mag, no room for rssi
			report.data[15] = 0; // rssi is always -0dBm for hid from tracker
		report.data[1] = 0; // id is always 0 for hid from tracker
		if (report_sent + report_count >= REPORT_COUNT) // overflow
			return;
		memcpy(&reports[sizeof(report) * (report_sent + report_count)], &report, sizeof(report));
		report_count++;
	}
#endif
}
```

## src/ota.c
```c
/*
	SlimeVR Code is placed under the MIT license
	Copyright (c) 2026 SlimeVR Contributors

	Permission is hereby granted, free of charge, to any person obtaining a copy
	of this software and associated documentation files (the "Software"), to deal
	in the Software without restriction, including without limitation the rights
	to use, copy, modify, merge, publish, distribute, sublicense, and/or sell
	copies of the Software, and to permit persons to whom the Software is
	furnished to do so, subject to the following conditions:

	The above copyright notice and this permission notice shall be included in
	all copies or substantial portions of the Software.

	THE SOFTWARE IS PROVIDED "AS IS", WITHOUT WARRANTY OF ANY KIND, EXPRESS OR
	IMPLIED, INCLUDING BUT NOT LIMITED TO THE WARRANTIES OF MERCHANTABILITY,
	FITNESS FOR A PARTICULAR PURPOSE AND NONINFRINGEMENT. IN NO EVENT SHALL THE
	AUTHORS OR COPYRIGHT HOLDERS BE LIABLE FOR ANY CLAIM, DAMAGES OR OTHER
	LIABILITY, WHETHER IN AN ACTION OF CONTRACT, TORT OR OTHERWISE, ARISING FROM,
	OUT OF OR IN CONNECTION WITH THE SOFTWARE OR THE USE OR OTHER DEALINGS IN
	THE SOFTWARE.
*/
#include "ota.h"

#if CONFIG_TRACKER_OTA

#include "ota_proto.h"
#include "connection/esb.h"

#include <string.h>
#include <zephyr/kernel.h>
#include <zephyr/logging/log.h>
#include <zephyr/dfu/mcuboot.h>
#include <zephyr/dfu/flash_img.h>
#include <zephyr/storage/flash_map.h>
#include <zephyr/sys/crc.h>
#include <zephyr/sys/reboot.h>

LOG_MODULE_REGISTER(ota, LOG_LEVEL_INF);

#define FRAME_WAIT_MS 20      // a frame with its retransmits is done well within this
#define STALL_TIMEOUT_MS 5000 // no chunk for this long: give up, keep the running image
#define DONE_REPEATS 5

/* ---- self-confirm of a new image ---- */

static atomic_t acked;
static K_SEM_DEFINE(confirm_sem, 0, 1);

void ota_tx_acked(void)
{
	if (atomic_inc(&acked) + 1 == CONFIG_TRACKER_OTA_CONFIRM_ACKS)
		k_sem_give(&confirm_sem);
}

// A swapped-in image runs as a test: MCUboot swaps the previous one back on the next reboot
// unless it is confirmed. Confirm only once the receiver has heard this image, so an image that
// boots but cannot track or reach the receiver is rolled back.
static void ota_confirm_thread(void)
{
	if (boot_is_img_confirmed())
		return;
	if (CONFIG_TRACKER_OTA_CONFIRM_ACKS == 0) {
		LOG_WRN("New image, never confirmed (TRACKER_OTA_CONFIRM_ACKS=0): the next reboot rolls back");
		return;
	}
	LOG_INF("New image: confirming after %d frames acknowledged by the receiver",
		CONFIG_TRACKER_OTA_CONFIRM_ACKS);
	k_sem_take(&confirm_sem, K_FOREVER);
	int err = boot_write_img_confirmed();
	if (err)
		LOG_ERR("Confirming the image failed: %d", err);
	else
		LOG_INF("Image confirmed");
}

// Its own stack: the flash write needs more than the system workqueue has.
K_THREAD_DEFINE(ota_confirm_thread_id, 1024, ota_confirm_thread, NULL, NULL, NULL, 7, 0, 0);

/* ---- receiving an update ---- */

enum { OTA_IDLE, OTA_OFFERED, OTA_ACTIVE };

static atomic_t state = ATOMIC_INIT(OTA_IDLE);
static uint8_t own_id;
static uint8_t offer[OTA_OFFER_LEN]; // as received; checked by the thread
static uint8_t offer_len;
static uint8_t session;
static uint32_t offer_size, offer_crc;
static uint32_t board_crc;

static volatile uint32_t wanted;       // position (session, offset) of the chunk being asked for
static uint8_t chunk[OTA_CHUNK_MAX];
static volatile uint8_t chunk_len;
static atomic_t chunk_ready;
static K_SEM_DEFINE(start_sem, 0, 1);
static K_SEM_DEFINE(tx_sem, 0, 1);

static uint32_t received; // bytes written so far, for the status
static int last_result = -1;

bool ota_active(void)
{
	return atomic_get(&state) != OTA_IDLE;
}

void ota_rx_ack(const uint8_t *data, uint8_t len, uint8_t tracker_id)
{
	if (len >= OTA_OFFER_MIN_LEN && data[0] == OTA_MSG_OFFER) {
		// Any version of the protocol starts its offer with [type][tracker id][protocol]: take it
		// for the thread, which checks it and answers what it cannot take
		if (data[1] != tracker_id || atomic_get(&state) != OTA_IDLE)
			return;
		offer_len = MIN(len, sizeof(offer));
		memcpy(offer, data, offer_len);
		own_id = tracker_id;
		atomic_set(&state, OTA_OFFERED);
		k_sem_give(&start_sem);
		return;
	}
	if (len > OTA_CHUNK_HEADER && data[0] == OTA_MSG_CHUNK && atomic_get(&state) == OTA_ACTIVE) {
		if (ota_get_u24(&data[1]) != wanted || atomic_get(&chunk_ready))
			return; // not the one asked for: queued before the last request, or by an earlier update
		chunk_len = MIN(len - OTA_CHUNK_HEADER, OTA_CHUNK_MAX);
		memcpy(chunk, &data[OTA_CHUNK_HEADER], chunk_len);
		atomic_set(&chunk_ready, 1);
	}
}

void ota_tx_done(void)
{
	// The ACK payload of a frame is handled in the same interrupt, right after this: by the time
	// the thread runs, a chunk that came with this ACK is in place.
	if (atomic_get(&state) == OTA_ACTIVE)
		k_sem_give(&tx_sem);
}

static void send_done(uint8_t status)
{
	uint8_t msg[OTA_DONE_LEN] = {OTA_MSG_DONE, own_id, status, OTA_PROTOCOL};
	for (int i = 0; i < DONE_REPEATS; i++) {
		esb_write_ota(msg, sizeof(msg));
		k_msleep(5);
	}
}

// CRC32 of the first size bytes of the running image (slot 0 holds it as the update sent it:
// MCUboot header, image, TLVs)
static uint32_t running_image_crc(uint32_t size)
{
	static uint8_t buf[256];
	const struct flash_area *fa;
	if (flash_area_open(FIXED_PARTITION_ID(slot0_partition), &fa))
		return 0;
	uint32_t crc = 0;
	size = MIN(size, fa->fa_size);
	for (uint32_t off = 0; off < size; off += sizeof(buf)) {
		uint32_t n = MIN(sizeof(buf), size - off);
		if (flash_area_read(fa, off, buf, n)) {
			crc = 0;
			break;
		}
		crc = crc32_ieee_update(crc, buf, n);
	}
	flash_area_close(fa);
	return crc;
}

// The offer in offer[]: -1 to take it, or the status to refuse it with
static int check_offer(void)
{
	if (offer_len != OTA_OFFER_LEN || offer[2] != OTA_PROTOCOL) {
		LOG_WRN("Update offer in OTA protocol %u, this firmware speaks %u", offer[2], OTA_PROTOCOL);
		return OTA_STATUS_PROTOCOL;
	}
	session = offer[3];
	offer_size = ota_get_u32(&offer[4]);
	offer_crc = ota_get_u32(&offer[8]);
	if (ota_get_u32(&offer[12]) != board_crc)
		return OTA_STATUS_WRONG_BOARD;
	if (offer_size == 0 || offer_size > FIXED_PARTITION_SIZE(slot1_partition) - 0x1000 || // room for the trailer
	    offer_size > OTA_OFFSET_MASK)
		return OTA_STATUS_TOO_LARGE;
	// Slot 1 holds the previous image until this one is confirmed: writing it would lose the
	// fallback MCUboot swaps back to
	if (!boot_is_img_confirmed())
		return OTA_STATUS_PENDING;
	if (running_image_crc(offer_size) == offer_crc)
		return OTA_STATUS_SAME_IMAGE;
	return -1;
}

static int receive_image(void)
{
	static struct flash_img_context ctx; // large: not on the stack
	int err = flash_img_init(&ctx);
	if (err) {
		LOG_ERR("Slot 1 not available: %d", err);
		return OTA_STATUS_FLASH_ERROR;
	}
	uint32_t offset = 0, crc = 0;
	uint32_t next_log = offer_size / 10;
	int64_t start = k_uptime_get(), last_chunk = start;
	received = 0;
	while (offset < offer_size) {
		uint8_t req[OTA_REQ_LEN] = {OTA_MSG_REQ, own_id};
		wanted = ota_position(session, offset);
		ota_put_u24(&req[2], wanted);
		atomic_set(&chunk_ready, 0);
		k_sem_reset(&tx_sem);
		esb_write_ota(req, sizeof(req));
		// The receiver queues the chunk asked for, and it comes with the ACK of the next request:
		// ask again as soon as this frame is done until it is there.
		k_sem_take(&tx_sem, K_MSEC(FRAME_WAIT_MS));
		if (!atomic_get(&chunk_ready)) {
			if (k_uptime_get() - last_chunk > STALL_TIMEOUT_MS) {
				LOG_ERR("Update stalled at %u of %u bytes", offset, offer_size);
				return OTA_STATUS_TIMEOUT;
			}
			continue;
		}
		uint32_t n = MIN(chunk_len, offer_size - offset);
		crc = crc32_ieee_update(crc, chunk, n);
		err = flash_img_buffered_write(&ctx, chunk, n, false); // erases each page on the way
		if (err) {
			LOG_ERR("Writing slot 1 failed at %u: %d", offset, err);
			return OTA_STATUS_FLASH_ERROR;
		}
		offset += n;
		received = offset;
		last_chunk = k_uptime_get();
		if (offset >= next_log) {
			LOG_INF("Update: %u%% (%u bytes, %lld s)", (uint32_t)((uint64_t)offset * 100 / offer_size),
				offset, (k_uptime_get() - start) / 1000);
			next_log += offer_size / 10;
		}
	}
	err = flash_img_buffered_write(&ctx, NULL, 0, true);
	if (err) {
		LOG_ERR("Writing slot 1 failed at the end: %d", err);
		return OTA_STATUS_FLASH_ERROR;
	}
	if (crc != offer_crc) {
		LOG_ERR("Update CRC %08x, expected %08x", crc, offer_crc);
		return OTA_STATUS_CRC_ERROR;
	}
	LOG_INF("Update received: %u bytes in %lld s", offer_size, (k_uptime_get() - start) / 1000);
	return OTA_STATUS_INSTALLED;
}

static void ota_thread(void)
{
	board_crc = crc32_ieee((const uint8_t *)CONFIG_BOARD_TARGET, strlen(CONFIG_BOARD_TARGET));
	while (1) {
		k_sem_take(&start_sem, K_FOREVER);
		// OFFERED/ACTIVE already suppress duplicates during a transfer. Once idle,
		// validate and answer again: receiver reboot can reuse a session number,
		// and a failed transfer must remain retryable with the same image.
		int status = check_offer();
		if (status >= 0) {
			LOG_WRN("Update offer refused: %s", ota_status_name(status));
			last_result = status;
			send_done(status);
			atomic_set(&state, OTA_IDLE);
			continue;
		}
		LOG_INF("Update offered: %u bytes; tracking paused while receiving", offer_size);
		atomic_set(&state, OTA_ACTIVE);
		status = receive_image();
		last_result = status;
		if (status == OTA_STATUS_INSTALLED) {
			int err = boot_request_upgrade(BOOT_UPGRADE_TEST);
			if (err) {
				LOG_ERR("Marking slot 1 for the swap failed: %d", err);
				status = OTA_STATUS_FLASH_ERROR;
				last_result = status;
			}
		}
		send_done(status);
		if (status == OTA_STATUS_INSTALLED) {
			LOG_INF("Rebooting into the new image (MCUboot swaps it in, it confirms itself once heard)");
			k_msleep(100);
			sys_reboot(SYS_REBOOT_COLD);
		}
		LOG_WRN("Update failed (%s), tracking again with the running image", ota_status_name(status));
		atomic_set(&state, OTA_IDLE);
	}
}

K_THREAD_DEFINE(ota_thread_id, 2048, ota_thread, NULL, NULL, NULL, 6, 0, 0);

void ota_print_status(void)
{
	// BOOT_SWAP_TYPE_NONE is 1, the others follow (zephyr/dfu/mcuboot.h)
	static const char *const swap_names[] = {"none", "test", "perm", "revert", "fail"};
	int swap = mcuboot_swap_type();
	if (boot_is_img_confirmed())
		printk("Image: confirmed");
	else
		printk("Image: pending (%ld of %d frames acknowledged)", (long)atomic_get(&acked),
		       CONFIG_TRACKER_OTA_CONFIRM_ACKS);
	printk(", next boot: swap %s, OTA protocol %u\n",
	       swap >= BOOT_SWAP_TYPE_NONE && swap <= BOOT_SWAP_TYPE_FAIL ? swap_names[swap - BOOT_SWAP_TYPE_NONE] : "unknown",
	       OTA_PROTOCOL);
	if (ota_active())
		printk("Update: receiving, %u of %u bytes\n", received, offer_size);
	else if (last_result >= 0)
		printk("Update: last one %s (%d)\n", ota_status_name(last_result), last_result);
}

#endif
```
